# ESP32-S31 register map
Vendor: ESPRESSIF SYSTEMS (SHANGHAI) CO., LTD.; Series: ESP32 S-Series; File version: 1
CPU: RV32IMAFC r0p0, little endian, no MPU, FPU, 0 interrupt priority bits
Address unit: 32 bits
Registers are 32-bit, read-write, reset 0x0 unless marked. A register's access mark holds for its fields unless they carry their own. Offsets are from the block's base; [hi:lo] are bit positions.

## CNNT_SYS — Connectivity System Registers
Base 0x20359000
0x00 SYS_VER_DATE reset 0x20250926
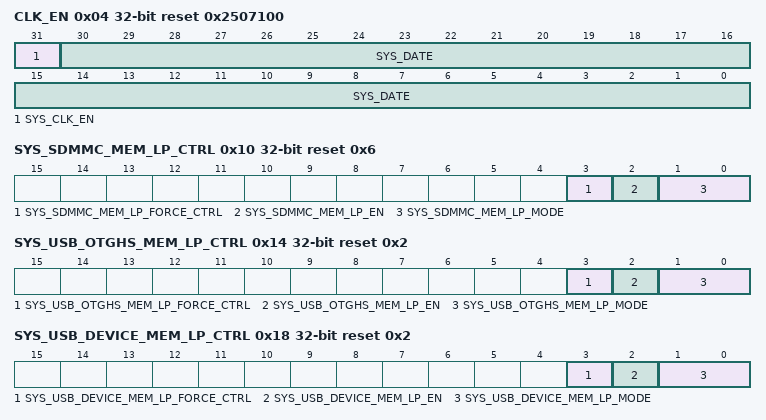
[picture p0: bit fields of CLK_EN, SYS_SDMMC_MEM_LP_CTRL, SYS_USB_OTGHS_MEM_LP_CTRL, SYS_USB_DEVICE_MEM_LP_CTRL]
0x04 CLK_EN reset 0x2507100
  [31] SYS_CLK_EN, [30:0] SYS_DATE
0x10 SYS_SDMMC_MEM_LP_CTRL reset 0x6
  [3] SYS_SDMMC_MEM_LP_FORCE_CTRL, [2] SYS_SDMMC_MEM_LP_EN, [1:0] SYS_SDMMC_MEM_LP_MODE
0x14 SYS_USB_OTGHS_MEM_LP_CTRL reset 0x2
  [3] SYS_USB_OTGHS_MEM_LP_FORCE_CTRL, [2] SYS_USB_OTGHS_MEM_LP_EN, [1:0] SYS_USB_OTGHS_MEM_LP_MODE
0x18 SYS_USB_DEVICE_MEM_LP_CTRL reset 0x2
  [3] SYS_USB_DEVICE_MEM_LP_FORCE_CTRL, [2] SYS_USB_DEVICE_MEM_LP_EN, [1:0] SYS_USB_DEVICE_MEM_LP_MODE
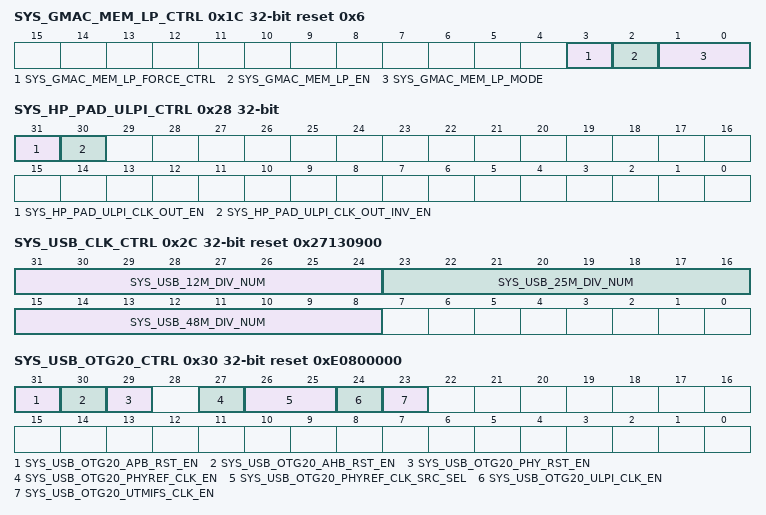
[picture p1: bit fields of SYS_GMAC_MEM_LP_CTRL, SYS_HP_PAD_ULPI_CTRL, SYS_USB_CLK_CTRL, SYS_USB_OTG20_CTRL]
0x1C SYS_GMAC_MEM_LP_CTRL reset 0x6
  [3] SYS_GMAC_MEM_LP_FORCE_CTRL, [2] SYS_GMAC_MEM_LP_EN, [1:0] SYS_GMAC_MEM_LP_MODE
0x20 SYS_SPRF_MEM_AUX_CTRL reset 0x2070
0x24 SYS_SDPRF_MEM_AUX_CTRL reset 0x2070
0x28 SYS_HP_PAD_ULPI_CTRL
  [31] SYS_HP_PAD_ULPI_CLK_OUT_EN, [30] SYS_HP_PAD_ULPI_CLK_OUT_INV_EN
0x2C SYS_USB_CLK_CTRL reset 0x27130900
  [31:24] SYS_USB_12M_DIV_NUM, [23:16] SYS_USB_25M_DIV_NUM, [15:8] SYS_USB_48M_DIV_NUM
0x30 SYS_USB_OTG20_CTRL reset 0xE0800000
  [31] SYS_USB_OTG20_APB_RST_EN, [30] SYS_USB_OTG20_AHB_RST_EN, [29] SYS_USB_OTG20_PHY_RST_EN, [27] SYS_USB_OTG20_PHYREF_CLK_EN, [26:25] SYS_USB_OTG20_PHYREF_CLK_SRC_SEL, [24] SYS_USB_OTG20_ULPI_CLK_EN, [23] SYS_USB_OTG20_UTMIFS_CLK_EN
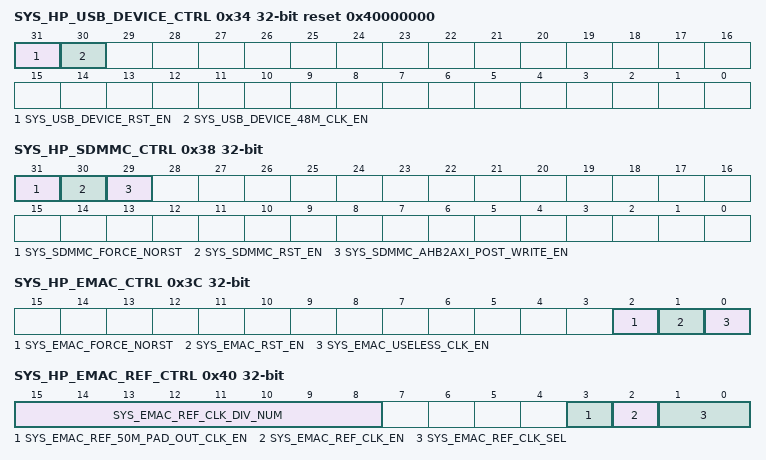
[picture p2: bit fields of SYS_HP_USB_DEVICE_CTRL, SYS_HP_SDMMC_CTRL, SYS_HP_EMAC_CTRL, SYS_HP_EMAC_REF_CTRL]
0x34 SYS_HP_USB_DEVICE_CTRL reset 0x40000000
  [31] SYS_USB_DEVICE_RST_EN, [30] SYS_USB_DEVICE_48M_CLK_EN
0x38 SYS_HP_SDMMC_CTRL
  [31] SYS_SDMMC_FORCE_NORST, [30] SYS_SDMMC_RST_EN, [29] SYS_SDMMC_AHB2AXI_POST_WRITE_EN
0x3C SYS_HP_EMAC_CTRL
  [2] SYS_EMAC_FORCE_NORST, [1] SYS_EMAC_RST_EN, [0] SYS_EMAC_USELESS_CLK_EN
0x40 SYS_HP_EMAC_REF_CTRL
  [15:8] SYS_EMAC_REF_CLK_DIV_NUM, [3] SYS_EMAC_REF_50M_PAD_OUT_CLK_EN, [2] SYS_EMAC_REF_CLK_EN, [1:0] SYS_EMAC_REF_CLK_SEL
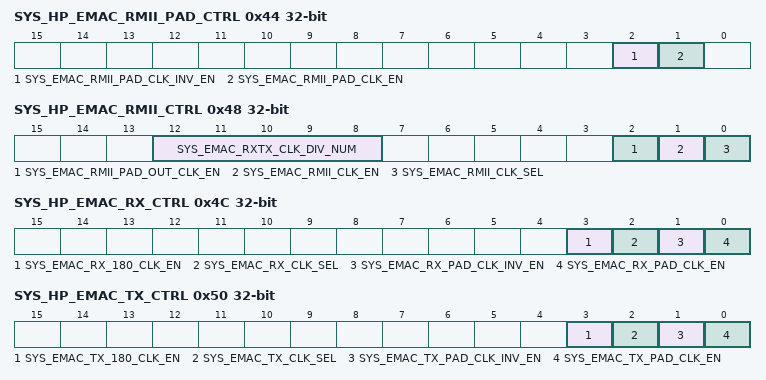
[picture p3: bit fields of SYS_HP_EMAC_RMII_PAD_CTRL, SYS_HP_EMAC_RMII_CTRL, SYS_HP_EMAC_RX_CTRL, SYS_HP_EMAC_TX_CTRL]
0x44 SYS_HP_EMAC_RMII_PAD_CTRL
  [2] SYS_EMAC_RMII_PAD_CLK_INV_EN, [1] SYS_EMAC_RMII_PAD_CLK_EN
0x48 SYS_HP_EMAC_RMII_CTRL
  [12:8] SYS_EMAC_RXTX_CLK_DIV_NUM, [2] SYS_EMAC_RMII_PAD_OUT_CLK_EN, [1] SYS_EMAC_RMII_CLK_EN, [0] SYS_EMAC_RMII_CLK_SEL
0x4C SYS_HP_EMAC_RX_CTRL
  [3] SYS_EMAC_RX_180_CLK_EN, [2] SYS_EMAC_RX_CLK_SEL, [1] SYS_EMAC_RX_PAD_CLK_INV_EN, [0] SYS_EMAC_RX_PAD_CLK_EN
0x50 SYS_HP_EMAC_TX_CTRL
  [3] SYS_EMAC_TX_180_CLK_EN, [2] SYS_EMAC_TX_CLK_SEL, [1] SYS_EMAC_TX_PAD_CLK_INV_EN, [0] SYS_EMAC_TX_PAD_CLK_EN
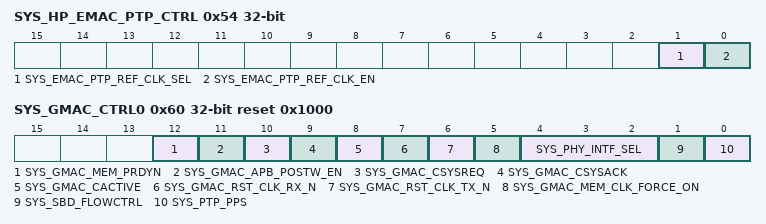
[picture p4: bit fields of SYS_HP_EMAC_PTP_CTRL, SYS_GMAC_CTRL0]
0x54 SYS_HP_EMAC_PTP_CTRL
  [1] SYS_EMAC_PTP_REF_CLK_SEL, [0] SYS_EMAC_PTP_REF_CLK_EN
0x58 SYS_CNNT_IOMUX_CTRL0
  [0] SYS_REG_CNNT_IOMUX_APB_RST_EN
0x5C SYS_SPRAM_MEM_AUX_CTRL reset 0x2070
0x60 SYS_GMAC_CTRL0 access per field reset 0x1000
  [12] SYS_GMAC_MEM_PRDYN ro, [11] SYS_GMAC_APB_POSTW_EN rw, [10] SYS_GMAC_CSYSREQ rw, [9] SYS_GMAC_CSYSACK ro, [8] SYS_GMAC_CACTIVE ro, [7] SYS_GMAC_RST_CLK_RX_N ro, [6] SYS_GMAC_RST_CLK_TX_N ro, [5] SYS_GMAC_MEM_CLK_FORCE_ON rw, [4:2] SYS_PHY_INTF_SEL rw, [1] SYS_SBD_FLOWCTRL rw, [0] SYS_PTP_PPS ro
0x64 SYS_GMAC_CTRL1 ro
  [31:0] SYS_PTP_TIMESTAMP_L
0x68 SYS_GMAC_CTRL2 ro
  [31:0] SYS_PTP_TIMESTAMP_H

## CORDIC — CORDIC Peripheral
Base 0x2039B000
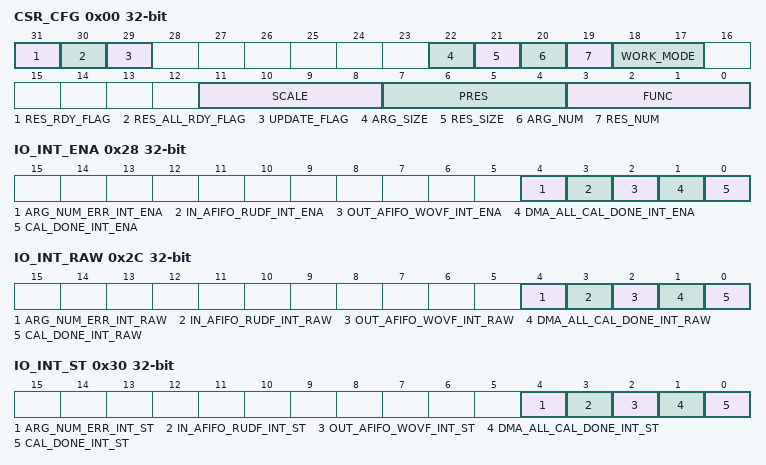
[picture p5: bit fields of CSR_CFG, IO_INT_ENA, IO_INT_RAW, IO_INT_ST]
0x00 CSR_CFG access per field — Cordic model config register
  [31] RES_RDY_FLAG ro — Used to indicate whether the operation result has been stored in the result register
  [30] RES_ALL_RDY_FLAG ro — Used to indicate whether the operation all result has been stored in the result register
  [29] UPDATE_FLAG rw — Used to synchronize register data to the computing core and start calculate
  [22] ARG_SIZE rw — Argument Size, 0: q1.15, 1: q1.31
  [21] RES_SIZE rw — Result Size, 0: q1.15, 1: q1.31
  [20] ARG_NUM rw — Argument number
  [19] RES_NUM rw — Result number
  [18:17] WORK_MODE rw — Select Cordic Module data transfer Mode,2'd0: reg_in,reg_out, no zero mode, 2'd1: dma_in, reg_out, no zero mode, 2'd2: dma_loop, 2'd3: reg_in, reg_out, zero mode
  [11:8] SCALE rw — The scaling of Input argument
  [7:4] PRES rw — Instruct the cordic calculate cycle number
  [3:0] FUNC rw — Used to inicate the type of operation currently being performed
0x04 ARG1 — Cordic argument 1 config register
  [31:0] DATA — First argument data for calculate
0x08 ARG2 — Cordic argument 2 config register
  [31:0] DATA — Second argument data for calculate
0x0C RES1 ro — Cordic result 1 receive register
  [31:0] DATA — First result data from calculate
0x10 RES2 ro — Cordic result 2 receive register
  [31:0] DATA — Second result data from calculate
0x28 IO_INT_ENA — Cordic interrupt enable singal configuration register.
  [4] ARG_NUM_ERR_INT_ENA — Write 1 to enable ARG_NUM_ERR_INT.
  [3] IN_AFIFO_RUDF_INT_ENA — Write 1 to enable IN_AFIFO_RUDF_INT.
  [2] OUT_AFIFO_WOVF_INT_ENA — Write 1 to enable OUT_AFIFO_WOVF_INT.
  [1] DMA_ALL_CAL_DONE_INT_ENA — Write 1 to enable DMA_ALL_CAL_DONE_INT.
  [0] CAL_DONE_INT_ENA — Write 1 to enable CAL_DONE_INT.
0x2C IO_INT_RAW ro — Cordic interrupt raw singal status register.
  [4] ARG_NUM_ERR_INT_RAW — The raw interrupt status of ARG_NUM_ERR_INT.
  [3] IN_AFIFO_RUDF_INT_RAW — The raw interrupt status of IN_AFIFO_RUDF_INT.
  [2] OUT_AFIFO_WOVF_INT_RAW — The raw interrupt status of OUT_AFIFO_WOVF_INT.
  [1] DMA_ALL_CAL_DONE_INT_RAW — The raw interrupt status of DMA_ALL_CAL_DONE_INT.
  [0] CAL_DONE_INT_RAW — The raw interrupt status of CAL_DONE_INT.
0x30 IO_INT_ST ro — Cordic interrupt singal status register.
  [4] ARG_NUM_ERR_INT_ST — The masked interrupt status of ARG_NUM_ERR_INT.
  [3] IN_AFIFO_RUDF_INT_ST — The masked interrupt status of IN_AFIFO_RUDF_INT.
  [2] OUT_AFIFO_WOVF_INT_ST — The masked interrupt status of OUT_AFIFO_WOVF_INT.
  [1] DMA_ALL_CAL_DONE_INT_ST — The masked interrupt status of DMA_ALL_CAL_DONE_INT.
  [0] CAL_DONE_INT_ST — The masked interrupt status of CAL_DONE_INT.
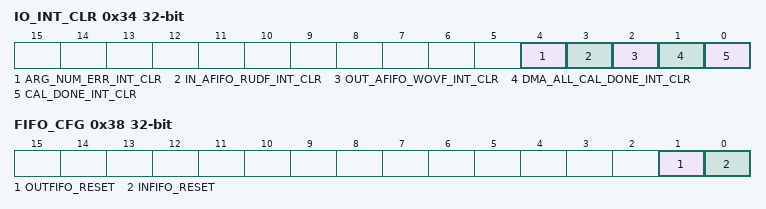
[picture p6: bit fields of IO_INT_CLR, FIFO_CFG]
0x34 IO_INT_CLR wo — Cordic interrupt clear singal configuration register.
  [4] ARG_NUM_ERR_INT_CLR — Write 1 to clear ARG_NUM_ERR_INT.
  [3] IN_AFIFO_RUDF_INT_CLR — Write 1 to clear IN_AFIFO_RUDF_INT.
  [2] OUT_AFIFO_WOVF_INT_CLR — Write 1 to clear OUT_AFIFO_WOVF_INT.
  [1] DMA_ALL_CAL_DONE_INT_CLR — Write 1 to clear DMA_ALL_CAL_DONE_INT.
  [0] CAL_DONE_INT_CLR — Write 1 to clear CAL_DONE_INT.
0x38 FIFO_CFG wo — Cordic FIFO configuration register.
  [1] OUTFIFO_RESET, [0] INFIFO_RESET
0x3C CLK — Cordic clk configuration register.
  [31] EN — Force clock on for this register file
0x40 VERSION reset 0x2411250
  [27:0] DATE — Version of this register file
